# STM8S903K3 register map
Vendor: STMicroelectronics; Series: STM8S/STM8AF, low density; File version: 1.0
CPU: other r1p0, big endian, no MPU, no FPU, 4 interrupt priority bits
Registers are 8-bit, read-write, reset 0x0 unless marked. A register's access mark holds for its fields unless they carry their own. Offsets are from the block's base; [hi:lo] are bit positions; {n}, {i} and the like mark numbered series.

## IWDG
Base 0x000050E0
0x00 KR — IWDG key register
  [7:0] KEY
0x01 PR — IWDG prescaler register
  [2:0] PR
0x02 RLR reset 0xFF — IWDG reload register
  [7:0] RL

## OPT
Base 0x00004800
0x00 OPT0 — Read-out protection (ROP)
0x01 OPT1 — User boot code (UBC)
0x02 NOPT1 reset 0xFF — User boot code (UBC) (complementary byte)
0x03 OPT2 — Alternate function remapping (AFR)
0x04 NOPT2 reset 0xFF — Alternate function remapping (AFR) (complementary byte)
0x05 OPT3 — Misc. option
0x06 NOPT3 reset 0xFF — Misc. option (complementary byte)
0x07 OPT4 — Clock option
0x08 NOPT4 reset 0xFF — Clock option (complementary byte)
0x09 OPT5 — HSE clock startup
0x0A NOPT5 reset 0xFF — HSE clock startup (complementary byte)

## PORTA
Base 0x00005000
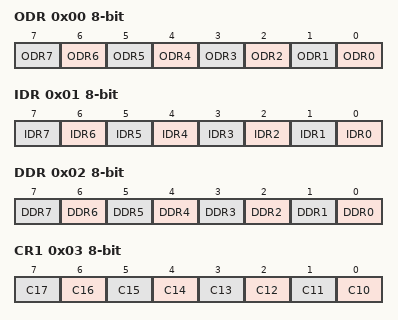
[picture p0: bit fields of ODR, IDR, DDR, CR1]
0x00 ODR — Port A data output latch register
  [n] ODR{n} (n=0..7)
0x01 IDR — Port A input pin value register
  [n] IDR{n} (n=0..7)
0x02 DDR — Port A data direction register
  [n] DDR{n} (n=0..7)
0x03 CR1 — Port A control register 1
  [n-10] C{n} (n=10..17)
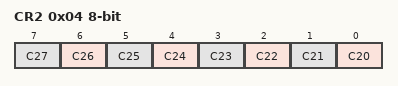
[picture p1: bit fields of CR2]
0x04 CR2 — Port A control register 2
  [n-20] C{n} (n=20..27)

## PORTB
Base 0x00005005
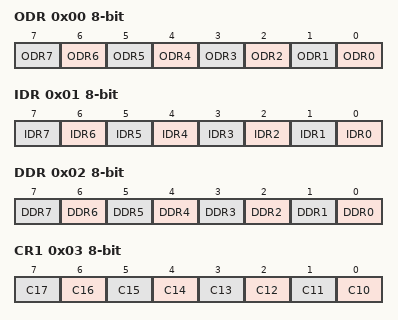
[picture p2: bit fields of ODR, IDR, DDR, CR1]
0x00 ODR — Port B data output latch register
  [n] ODR{n} (n=0..7)
0x01 IDR — Port B input pin value register
  [n] IDR{n} (n=0..7)
0x02 DDR — Port B data direction register
  [n] DDR{n} (n=0..7)
0x03 CR1 — Port B control register 1
  [n-10] C{n} (n=10..17)
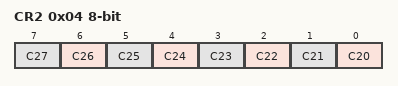
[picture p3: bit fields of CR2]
0x04 CR2 — Port B control register 2
  [n-20] C{n} (n=20..27)

## PORTC
Base 0x0000500A
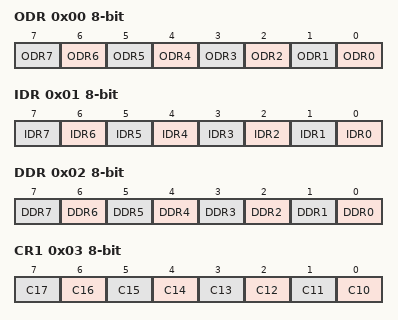
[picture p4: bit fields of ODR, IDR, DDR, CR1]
0x00 ODR — Port C data output latch register
  [n] ODR{n} (n=0..7)
0x01 IDR — Port C input pin value register
  [n] IDR{n} (n=0..7)
0x02 DDR — Port C data direction register
  [n] DDR{n} (n=0..7)
0x03 CR1 — Port C control register 1
  [n-10] C{n} (n=10..17)
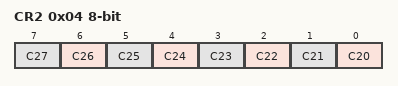
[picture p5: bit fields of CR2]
0x04 CR2 — Port C control register 2
  [n-20] C{n} (n=20..27)

## PORTD
Base 0x0000500F
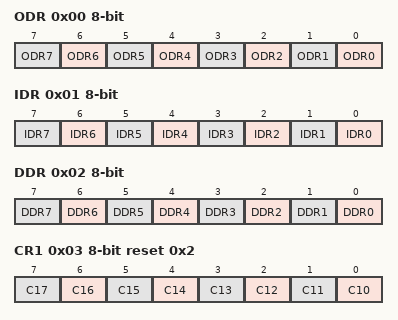
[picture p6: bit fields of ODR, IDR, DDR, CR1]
0x00 ODR — Port D data output latch register
  [n] ODR{n} (n=0..7)
0x01 IDR — Port D input pin value register
  [n] IDR{n} (n=0..7)
0x02 DDR — Port D data direction register
  [n] DDR{n} (n=0..7)
0x03 CR1 reset 0x2 — Port D control register 1
  [n-10] C{n} (n=10..17)
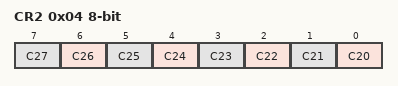
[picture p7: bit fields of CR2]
0x04 CR2 — Port D control register 2
  [n-20] C{n} (n=20..27)

## PORTE
Base 0x00005014
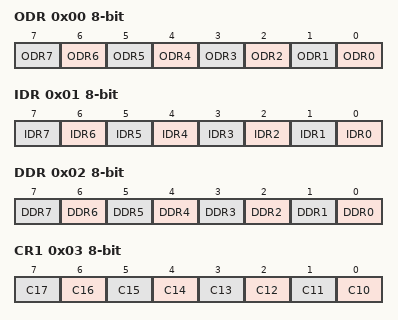
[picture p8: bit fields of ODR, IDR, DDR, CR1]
0x00 ODR — Port E data output latch register
  [n] ODR{n} (n=0..7)
0x01 IDR — Port E input pin value register
  [n] IDR{n} (n=0..7)
0x02 DDR — Port E data direction register
  [n] DDR{n} (n=0..7)
0x03 CR1 — Port E control register 1
  [n-10] C{n} (n=10..17)
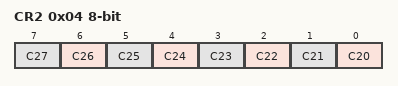
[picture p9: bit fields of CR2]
0x04 CR2 — Port E control register 2
  [n-20] C{n} (n=20..27)

## PORTF
Base 0x00005019
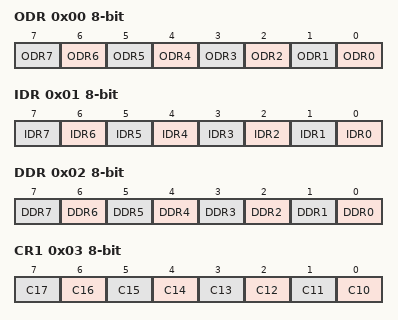
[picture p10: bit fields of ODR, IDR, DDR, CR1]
0x00 ODR — Port F data output latch register
  [n] ODR{n} (n=0..7)
0x01 IDR — Port F input pin value register
  [n] IDR{n} (n=0..7)
0x02 DDR — Port F data direction register
  [n] DDR{n} (n=0..7)
0x03 CR1 — Port F control register 1
  [n-10] C{n} (n=10..17)
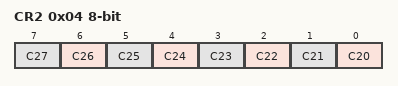
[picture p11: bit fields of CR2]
0x04 CR2 — Port F control register 2
  [n-20] C{n} (n=20..27)

## RST
Base 0x000050B3
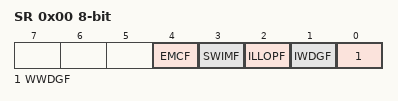
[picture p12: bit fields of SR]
0x00 SR — Reset status register
  [4] EMCF, [3] SWIMF, [2] ILLOPF, [1] IWDGF, [0] WWDGF

## SPI
Base 0x00005200
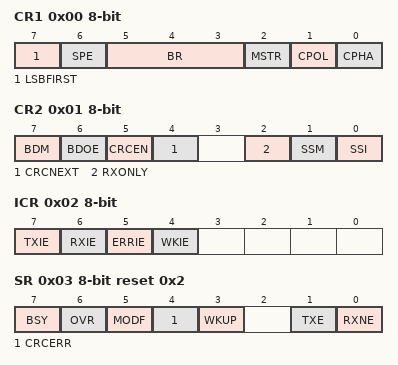
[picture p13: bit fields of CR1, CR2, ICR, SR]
0x00 CR1 — SPI control register 1
  [7] LSBFIRST, [6] SPE, [5:3] BR, [2] MSTR, [1] CPOL, [0] CPHA
0x01 CR2 — SPI control register 2
  [7] BDM, [6] BDOE, [5] CRCEN, [4] CRCNEXT, [2] RXONLY, [1] SSM, [0] SSI
0x02 ICR — SPI interrupt control register
  [7] TXIE, [6] RXIE, [5] ERRIE, [4] WKIE
0x03 SR reset 0x2 — SPI status register
  [7] BSY, [6] OVR, [5] MODF, [4] CRCERR, [3] WKUP, [1] TXE, [0] RXNE
0x04 DR — SPI data register
0x05 CRCPR reset 0x7 — SPI CRC polynomial register
  [7:0] CRCPOLY
0x06 RXCRCR reset 0xFF — SPI Rx CRC register
  [7:0] RXCRC
0x07 TXCRCR reset 0xFF — SPI Tx CRC register
  [7:0] TXCRC
